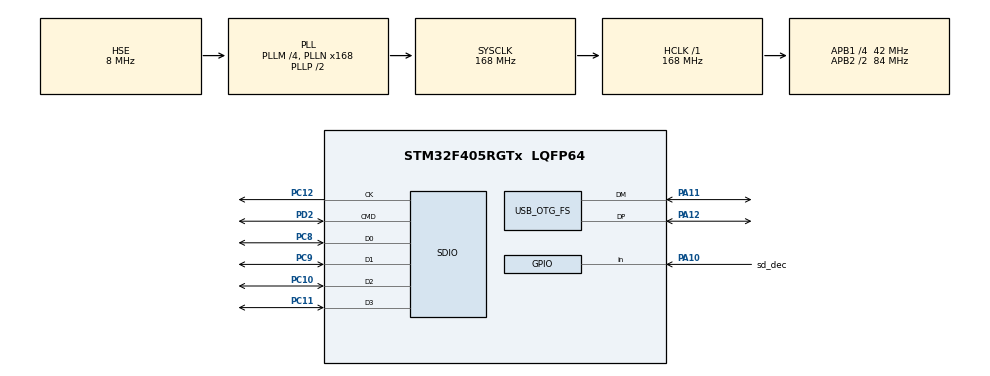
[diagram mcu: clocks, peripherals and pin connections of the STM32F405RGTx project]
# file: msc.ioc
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Dma.Request0=SDIO_RX
Dma.Request1=SDIO_TX
Dma.SDIO_RX.0.Direction=DMA_PERIPH_TO_MEMORY
Dma.SDIO_RX.0.FIFOMode=DMA_FIFOMODE_ENABLE
Dma.SDIO_RX.0.FIFOThreshold=DMA_FIFO_THRESHOLD_FULL
Dma.SDIO_RX.0.Instance=DMA2_Stream3
Dma.SDIO_RX.0.MemBurst=DMA_MBURST_INC4
Dma.SDIO_RX.0.MemDataAlignment=DMA_MDATAALIGN_WORD
Dma.SDIO_RX.0.MemInc=DMA_MINC_ENABLE
Dma.SDIO_RX.0.Mode=DMA_PFCTRL
Dma.SDIO_RX.0.PeriphBurst=DMA_PBURST_INC4
Dma.SDIO_RX.0.PeriphDataAlignment=DMA_PDATAALIGN_WORD
Dma.SDIO_RX.0.PeriphInc=DMA_PINC_DISABLE
Dma.SDIO_RX.0.Priority=DMA_PRIORITY_LOW
Dma.SDIO_TX.1.Direction=DMA_MEMORY_TO_PERIPH
Dma.SDIO_TX.1.FIFOMode=DMA_FIFOMODE_ENABLE
Dma.SDIO_TX.1.FIFOThreshold=DMA_FIFO_THRESHOLD_FULL
Dma.SDIO_TX.1.Instance=DMA2_Stream6
Dma.SDIO_TX.1.MemBurst=DMA_MBURST_INC4
Dma.SDIO_TX.1.MemDataAlignment=DMA_MDATAALIGN_WORD
Dma.SDIO_TX.1.MemInc=DMA_MINC_ENABLE
Dma.SDIO_TX.1.Mode=DMA_PFCTRL
Dma.SDIO_TX.1.PeriphBurst=DMA_PBURST_INC4
Dma.SDIO_TX.1.PeriphDataAlignment=DMA_PDATAALIGN_WORD
Dma.SDIO_TX.1.PeriphInc=DMA_PINC_DISABLE
Dma.SDIO_TX.1.Priority=DMA_PRIORITY_LOW
FATFS.BSP.number=1
FATFS._CODE_PAGE=437
FATFS._MAX_SS=512
FATFS._USE_LFN=2
FATFS0.BSP.STBoard=false
FATFS0.BSP.api=BusDriver
FATFS0.BSP.i2caddr=0
FATFS0.BSP.i2creg=0
FATFS0.BSP.instance=PA10
FATFS0.BSP.ip=GPIO
FATFS0.BSP.mode=Input
FATFS0.BSP.name=Detect_SDIO
FREERTOS.Tasks01=defaultTask,0,128,StartDefaultTask,Default,NULL
Mcu.Family=STM32F4
Mcu.Name=STM32F405RGTx
Mcu.Package=LQFP64
NVIC.DMA2_Stream3_IRQn=true\:7\:0\:true\:false\:true\:true
NVIC.DMA2_Stream6_IRQn=true\:7\:0\:true\:false\:true\:true
NVIC.OTG_FS_IRQn=true\:8\:0\:true\:false\:true\:true
NVIC.PriorityGroup=NVIC_PRIORITYGROUP_4
NVIC.SDIO_IRQn=true\:6\:0\:true\:false\:true\:true
NVIC.TIM2_IRQn=true\:0\:0\:false\:false\:true\:false
NVIC.TimeBase=TIM2_IRQn
NVIC.TimeBaseIP=TIM2
PA10.GPIO_Label=sd_dec
PA10.Signal=GPIO_Input
PA11.GPIO_Mode=GPIO_MODE_AF_PP
PA11.GPIO_PuPd=GPIO_NOPULL
PA11.GPIO_Speed=GPIO_SPEED_FREQ_VERY_HIGH
PA11.Mode=Device_Only
PA11.Signal=USB_OTG_FS_DM
PA12.GPIO_Mode=GPIO_MODE_AF_PP
PA12.GPIO_PuPd=GPIO_NOPULL
PA12.GPIO_Speed=GPIO_SPEED_FREQ_VERY_HIGH
PA12.Mode=Device_Only
PA12.Signal=USB_OTG_FS_DP
PA13.Mode=JTAG_4_pins
PA13.Signal=SYS_JTMS-SWDIO
PA14.Mode=JTAG_4_pins
PA14.Signal=SYS_JTCK-SWCLK
PA15.Mode=JTAG_4_pins
PA15.Signal=SYS_JTDI
PB3.Mode=JTAG_4_pins
PB3.Signal=SYS_JTDO-SWO
PC10.Mode=SD_4_bits_Wide_bus
PC10.Signal=SDIO_D2
PC11.Mode=SD_4_bits_Wide_bus
PC11.Signal=SDIO_D3
PC12.GPIO_Mode=GPIO_MODE_AF_PP
PC12.GPIO_PuPd=GPIO_PULLUP
PC12.GPIO_Speed_High_Default=GPIO_SPEED_FREQ_VERY_HIGH
PC12.Mode=SD_4_bits_Wide_bus
PC12.Signal=SDIO_CK
PC8.GPIO_Mode=GPIO_MODE_AF_PP
PC8.GPIO_PuPd=GPIO_PULLUP
PC8.GPIO_Speed_High_Default=GPIO_SPEED_FREQ_VERY_HIGH
PC8.Mode=SD_4_bits_Wide_bus
PC8.Signal=SDIO_D0
PC9.Mode=SD_4_bits_Wide_bus
PC9.Signal=SDIO_D1
PD2.GPIO_Mode=GPIO_MODE_AF_PP
PD2.GPIO_PuPd=GPIO_PULLUP
PD2.GPIO_Speed_High_Default=GPIO_SPEED_FREQ_VERY_HIGH
PD2.Mode=SD_4_bits_Wide_bus
PD2.Signal=SDIO_CMD
PH0-OSC_IN.Mode=HSE-External-Oscillator
PH0-OSC_IN.Signal=RCC_OSC_IN
PH1-OSC_OUT.Mode=HSE-External-Oscillator
PH1-OSC_OUT.Signal=RCC_OSC_OUT
ProjectManager.HeapSize=0x2000
ProjectManager.StackSize=0x4000
ProjectManager.TargetToolchain=EWARM
RCC.48MHZClocksFreq_Value=48000000
RCC.AHBFreq_Value=168000000
RCC.APB1CLKDivider=RCC_HCLK_DIV4
RCC.APB1Freq_Value=42000000
RCC.APB1TimFreq_Value=84000000
RCC.APB2CLKDivider=RCC_HCLK_DIV2
RCC.APB2Freq_Value=84000000
RCC.APB2TimFreq_Value=168000000
RCC.CortexFreq_Value=168000000
RCC.HCLKFreq_Value=168000000
RCC.HSE_VALUE=8000000
RCC.HSI_VALUE=16000000
RCC.LSE_VALUE=32768
RCC.PLLM=4
RCC.PLLN=168
RCC.PLLQ=7
RCC.SYSCLKFreq_VALUE=168000000
RCC.SYSCLKSource=RCC_SYSCLKSOURCE_PLLCLK
RCC.VCOOutputFreq_Value=336000000
SDIO.ClockDiv=0
USB_DEVICE.CLASS_NAME_FS=MSC
USB_DEVICE.MSC_MEDIA_PACKET-MSC_FS=4096
USB_DEVICE.USBD_SELF_POWERED-MSC_FS=1
USB_DEVICE.VirtualMode-MSC_FS=Msc
USB_DEVICE.VirtualModeFS=Msc_FS
USB_OTG_FS.VirtualMode=Device_Only
USB_OTG_FS.vbus_sensing_enable=DISABLE
VP_FATFS_VS_SDIO.Mode=SDIO
VP_FREERTOS_VS_ENABLE.Mode=Enabled
VP_SYS_VS_tim2.Mode=TIM2
VP_USB_DEVICE_VS_USB_DEVICE_MSC_FS.Mode=MSC_FS
board=msc

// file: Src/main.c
/**
  ******************************************************************************
  * File Name          : main.c
  * Description        : Main program body
  ******************************************************************************
  * This notice applies to any and all portions of this file
  * that are not between comment pairs USER CODE BEGIN and
  * USER CODE END. Other portions of this file, whether
  * inserted by the user or by software development tools
  * are owned by their respective copyright owners.
  *
  * Copyright (c) 2018 STMicroelectronics International N.V.
  * All rights reserved.
  *
  * Redistribution and use in source and binary forms, with or without
  * modification, are permitted, provided that the following conditions are met:
  *
  * 1. Redistribution of source code must retain the above copyright notice,
  *    this list of conditions and the following disclaimer.
  * 2. Redistributions in binary form must reproduce the above copyright notice,
  *    this list of conditions and the following disclaimer in the documentation
  *    and/or other materials provided with the distribution.
  * 3. Neither the name of STMicroelectronics nor the names of other
  *    contributors to this software may be used to endorse or promote products
  *    derived from this software without specific written permission.
  * 4. This software, including modifications and/or derivative works of this
  *    software, must execute solely and exclusively on microcontroller or
  *    microprocessor devices manufactured by or for STMicroelectronics.
  * 5. Redistribution and use of this software other than as permitted under
  *    this license is void and will automatically terminate your rights under
  *    this license.
  *
  * THIS SOFTWARE IS PROVIDED BY STMICROELECTRONICS AND CONTRIBUTORS "AS IS"
  * AND ANY EXPRESS, IMPLIED OR STATUTORY WARRANTIES, INCLUDING, BUT NOT
  * LIMITED TO, THE IMPLIED WARRANTIES OF MERCHANTABILITY, FITNESS FOR A
  * PARTICULAR PURPOSE AND NON-INFRINGEMENT OF THIRD PARTY INTELLECTUAL PROPERTY
  * RIGHTS ARE DISCLAIMED TO THE FULLEST EXTENT PERMITTED BY LAW. IN NO EVENT
  * SHALL STMICROELECTRONICS OR CONTRIBUTORS BE LIABLE FOR ANY DIRECT, INDIRECT,
  * INCIDENTAL, SPECIAL, EXEMPLARY, OR CONSEQUENTIAL DAMAGES (INCLUDING, BUT NOT
  * LIMITED TO, PROCUREMENT OF SUBSTITUTE GOODS OR SERVICES; LOSS OF USE, DATA,
  * OR PROFITS; OR BUSINESS INTERRUPTION) HOWEVER CAUSED AND ON ANY THEORY OF
  * LIABILITY, WHETHER IN CONTRACT, STRICT LIABILITY, OR TORT (INCLUDING
  * NEGLIGENCE OR OTHERWISE) ARISING IN ANY WAY OUT OF THE USE OF THIS SOFTWARE,
  * EVEN IF ADVISED OF THE POSSIBILITY OF SUCH DAMAGE.
  *
  ******************************************************************************
  */
#include "main.h"
#include "stm32f4xx_hal.h"
#include "cmsis_os.h"
#include "fatfs.h"
#include "usb_device.h"

SD_HandleTypeDef hsd;
DMA_HandleTypeDef hdma_sdio_rx;
DMA_HandleTypeDef hdma_sdio_tx;

osThreadId defaultTaskHandle;

/* USER CODE BEGIN PV */
/* Private variables ---------------------------------------------------------*/

/* USER CODE END PV */

void SystemClock_Config(void);
static void MX_GPIO_Init(void);
static void MX_DMA_Init(void);
static void MX_SDIO_SD_Init(void);
void StartDefaultTask(void const * argument);

/* USER CODE BEGIN PFP */
/* Private function prototypes -----------------------------------------------*/

/* USER CODE END PFP */

int main(void)
{

  /* MCU Configuration----------------------------------------------------------*/

  /* Reset of all peripherals, Initializes the Flash interface and the Systick. */
  HAL_Init();

  /* Configure the system clock */
  SystemClock_Config();

  /* Initialize all configured peripherals */
  MX_GPIO_Init();
  MX_DMA_Init();
  MX_SDIO_SD_Init();

  /* USER CODE BEGIN 2 */
	__HAL_SD_DMA_ENABLE(&hsd);
  /* USER CODE END 2 */

  /* Create the thread(s) */
  /* definition and creation of defaultTask */
  osThreadDef(defaultTask, StartDefaultTask, osPriorityNormal, 0, 128);
  defaultTaskHandle = osThreadCreate(osThread(defaultTask), NULL);

  /* Start scheduler */
  osKernelStart();

  /* We should never get here as control is now taken by the scheduler */

  /* Infinite loop */
  while (1)
  {

  }

}

/** System Clock Configuration
*/
void SystemClock_Config(void)
{

  RCC_OscInitTypeDef RCC_OscInitStruct;
  RCC_ClkInitTypeDef RCC_ClkInitStruct;

    /**Configure the main internal regulator output voltage
    */
  __HAL_RCC_PWR_CLK_ENABLE();

  __HAL_PWR_VOLTAGESCALING_CONFIG(PWR_REGULATOR_VOLTAGE_SCALE1);

    /**Initializes the CPU, AHB and APB busses clocks
    */
  RCC_OscInitStruct.OscillatorType = RCC_OSCILLATORTYPE_HSE;
  RCC_OscInitStruct.HSEState = RCC_HSE_ON;
  RCC_OscInitStruct.PLL.PLLState = RCC_PLL_ON;
  RCC_OscInitStruct.PLL.PLLSource = RCC_PLLSOURCE_HSE;
  RCC_OscInitStruct.PLL.PLLM = 4;
  RCC_OscInitStruct.PLL.PLLN = 168;
  RCC_OscInitStruct.PLL.PLLP = RCC_PLLP_DIV2;
  RCC_OscInitStruct.PLL.PLLQ = 7;
  if (HAL_RCC_OscConfig(&RCC_OscInitStruct) != HAL_OK)
  {
    _Error_Handler(__FILE__, __LINE__);
  }

    /**Initializes the CPU, AHB and APB busses clocks
    */
  RCC_ClkInitStruct.ClockType = RCC_CLOCKTYPE_HCLK|RCC_CLOCKTYPE_SYSCLK
                              |RCC_CLOCKTYPE_PCLK1|RCC_CLOCKTYPE_PCLK2;
  RCC_ClkInitStruct.SYSCLKSource = RCC_SYSCLKSOURCE_PLLCLK;
  RCC_ClkInitStruct.AHBCLKDivider = RCC_SYSCLK_DIV1;
  RCC_ClkInitStruct.APB1CLKDivider = RCC_HCLK_DIV4;
  RCC_ClkInitStruct.APB2CLKDivider = RCC_HCLK_DIV2;

  if (HAL_RCC_ClockConfig(&RCC_ClkInitStruct, FLASH_LATENCY_5) != HAL_OK)
  {
    _Error_Handler(__FILE__, __LINE__);
  }

    /**Configure the Systick interrupt time
    */
  HAL_SYSTICK_Config(HAL_RCC_GetHCLKFreq()/1000);

    /**Configure the Systick
    */
  HAL_SYSTICK_CLKSourceConfig(SYSTICK_CLKSOURCE_HCLK);

  /* SysTick_IRQn interrupt configuration */
  HAL_NVIC_SetPriority(SysTick_IRQn, 15, 0);
}

/* SDIO init function */
static void MX_SDIO_SD_Init(void)
{

  hsd.Instance = SDIO;
  hsd.Init.ClockEdge = SDIO_CLOCK_EDGE_RISING;
  hsd.Init.ClockBypass = SDIO_CLOCK_BYPASS_DISABLE;
  hsd.Init.ClockPowerSave = SDIO_CLOCK_POWER_SAVE_DISABLE;
  hsd.Init.BusWide = SDIO_BUS_WIDE_1B;
  hsd.Init.HardwareFlowControl = SDIO_HARDWARE_FLOW_CONTROL_DISABLE;
  hsd.Init.ClockDiv = 0;

}

static void MX_DMA_Init(void)
{
  /* DMA controller clock enable */
  __HAL_RCC_DMA2_CLK_ENABLE();

  /* DMA interrupt init */
  /* DMA2_Stream3_IRQn interrupt configuration */
  HAL_NVIC_SetPriority(DMA2_Stream3_IRQn, 7, 0);
  HAL_NVIC_EnableIRQ(DMA2_Stream3_IRQn);
  /* DMA2_Stream6_IRQn interrupt configuration */
  HAL_NVIC_SetPriority(DMA2_Stream6_IRQn, 7, 0);
  HAL_NVIC_EnableIRQ(DMA2_Stream6_IRQn);

}

/** Configure pins as
        * Analog
        * Input
        * Output
        * EVENT_OUT
        * EXTI
*/
static void MX_GPIO_Init(void)
{

  GPIO_InitTypeDef GPIO_InitStruct;

  /* GPIO Ports Clock Enable */
  __HAL_RCC_GPIOH_CLK_ENABLE();
  __HAL_RCC_GPIOC_CLK_ENABLE();
  __HAL_RCC_GPIOA_CLK_ENABLE();
  __HAL_RCC_GPIOD_CLK_ENABLE();
  __HAL_RCC_GPIOB_CLK_ENABLE();

  /*Configure GPIO pin : sd_dec_Pin */
  GPIO_InitStruct.Pin = sd_dec_Pin;
  GPIO_InitStruct.Mode = GPIO_MODE_INPUT;
  GPIO_InitStruct.Pull = GPIO_NOPULL;
  HAL_GPIO_Init(sd_dec_GPIO_Port, &GPIO_InitStruct);

}

/* StartDefaultTask function */
void StartDefaultTask(void const * argument)
{
  /* init code for FATFS */
  MX_FATFS_Init();

  /* init code for USB_DEVICE */
  MX_USB_DEVICE_Init();

  for(;;)
  {
    osDelay(1);
  }
}

void HAL_TIM_PeriodElapsedCallback(TIM_HandleTypeDef *htim)
{
  if (htim->Instance == TIM2) {
    HAL_IncTick();
  }
}

void _Error_Handler(char * file, int line)
{
  while(1)
  {
  }
}

/************************ (C) COPYRIGHT STMicroelectronics *****END OF FILE****/
